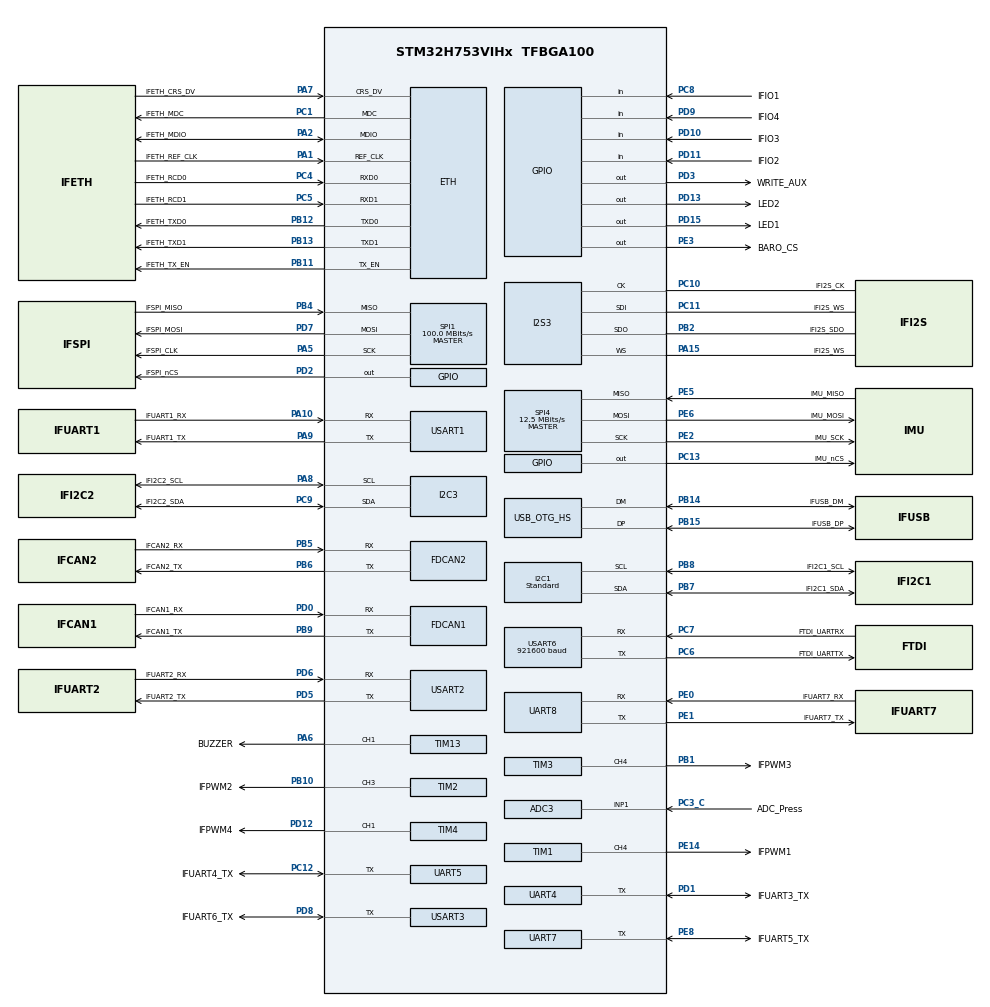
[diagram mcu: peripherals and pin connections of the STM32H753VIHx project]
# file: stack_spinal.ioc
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ADC3.Channel-1\#ChannelRegularConversion=ADC_CHANNEL_1
ADC3.NbrOfConversionFlag=1
ADC3.OffsetNumber-1\#ChannelRegularConversion=ADC_OFFSET_NONE
ADC3.OffsetSignedSaturation-1\#ChannelRegularConversion=DISABLE
ADC3.Rank-1\#ChannelRegularConversion=1
ADC3.SamplingTime-1\#ChannelRegularConversion=ADC_SAMPLETIME_1CYCLE_5
CORTEX_M7.AccessPermission-Cortex_Memory_Protection_Unit_Region0_Settings=MPU_REGION_FULL_ACCESS
CORTEX_M7.AccessPermission-Cortex_Memory_Protection_Unit_Region10_Settings=MPU_REGION_FULL_ACCESS
CORTEX_M7.AccessPermission-Cortex_Memory_Protection_Unit_Region11_Settings=MPU_REGION_FULL_ACCESS
CORTEX_M7.AccessPermission-Cortex_Memory_Protection_Unit_Region1_Settings=MPU_REGION_FULL_ACCESS
CORTEX_M7.AccessPermission-Cortex_Memory_Protection_Unit_Region2_Settings=MPU_REGION_FULL_ACCESS
CORTEX_M7.AccessPermission-Cortex_Memory_Protection_Unit_Region3_Settings=MPU_REGION_FULL_ACCESS
CORTEX_M7.AccessPermission-Cortex_Memory_Protection_Unit_Region4_Settings=MPU_REGION_FULL_ACCESS
CORTEX_M7.AccessPermission-Cortex_Memory_Protection_Unit_Region5_Settings=MPU_REGION_FULL_ACCESS
CORTEX_M7.AccessPermission-Cortex_Memory_Protection_Unit_Region6_Settings=MPU_REGION_FULL_ACCESS
CORTEX_M7.AccessPermission-Cortex_Memory_Protection_Unit_Region7_Settings=MPU_REGION_FULL_ACCESS
CORTEX_M7.AccessPermission-Cortex_Memory_Protection_Unit_Region9_Settings=MPU_REGION_FULL_ACCESS
CORTEX_M7.BaseAddress-Cortex_Memory_Protection_Unit_Region0_Settings=0x24040000
CORTEX_M7.BaseAddress-Cortex_Memory_Protection_Unit_Region10_Settings=0x24045100
CORTEX_M7.BaseAddress-Cortex_Memory_Protection_Unit_Region11_Settings=0x24045180
CORTEX_M7.BaseAddress-Cortex_Memory_Protection_Unit_Region1_Settings=0x24040000
CORTEX_M7.BaseAddress-Cortex_Memory_Protection_Unit_Region2_Settings=0x24044400
CORTEX_M7.BaseAddress-Cortex_Memory_Protection_Unit_Region3_Settings=0x30040000
CORTEX_M7.BaseAddress-Cortex_Memory_Protection_Unit_Region4_Settings=0x30044000
CORTEX_M7.BaseAddress-Cortex_Memory_Protection_Unit_Region5_Settings=0x30040000
CORTEX_M7.BaseAddress-Cortex_Memory_Protection_Unit_Region6_Settings=0x24044800
CORTEX_M7.BaseAddress-Cortex_Memory_Protection_Unit_Region7_Settings=0x24044C00
CORTEX_M7.BaseAddress-Cortex_Memory_Protection_Unit_Region8_Settings=0x24045000
CORTEX_M7.BaseAddress-Cortex_Memory_Protection_Unit_Region9_Settings=0x24045080
CORTEX_M7.CPU_DCache=Enabled
CORTEX_M7.CPU_ICache=Enabled
CORTEX_M7.Enable-Cortex_Memory_Protection_Unit_Region0_Settings=MPU_REGION_ENABLE
CORTEX_M7.Enable-Cortex_Memory_Protection_Unit_Region10_Settings=MPU_REGION_ENABLE
CORTEX_M7.Enable-Cortex_Memory_Protection_Unit_Region11_Settings=MPU_REGION_ENABLE
CORTEX_M7.Enable-Cortex_Memory_Protection_Unit_Region1_Settings=MPU_REGION_ENABLE
CORTEX_M7.Enable-Cortex_Memory_Protection_Unit_Region2_Settings=MPU_REGION_ENABLE
CORTEX_M7.Enable-Cortex_Memory_Protection_Unit_Region3_Settings=MPU_REGION_ENABLE
CORTEX_M7.Enable-Cortex_Memory_Protection_Unit_Region4_Settings=MPU_REGION_ENABLE
CORTEX_M7.Enable-Cortex_Memory_Protection_Unit_Region5_Settings=MPU_REGION_ENABLE
CORTEX_M7.Enable-Cortex_Memory_Protection_Unit_Region6_Settings=MPU_REGION_ENABLE
CORTEX_M7.Enable-Cortex_Memory_Protection_Unit_Region7_Settings=MPU_REGION_ENABLE
CORTEX_M7.Enable-Cortex_Memory_Protection_Unit_Region8_Settings=MPU_REGION_ENABLE
CORTEX_M7.Enable-Cortex_Memory_Protection_Unit_Region9_Settings=MPU_REGION_ENABLE
CORTEX_M7.IsBufferable-Cortex_Memory_Protection_Unit_Region5_Settings=MPU_ACCESS_BUFFERABLE
CORTEX_M7.IsCacheable-Cortex_Memory_Protection_Unit_Region1_Settings=MPU_ACCESS_CACHEABLE
CORTEX_M7.IsCacheable-Cortex_Memory_Protection_Unit_Region4_Settings=MPU_ACCESS_CACHEABLE
CORTEX_M7.IsShareable-Cortex_Memory_Protection_Unit_Region1_Settings=MPU_ACCESS_SHAREABLE
CORTEX_M7.MPU_Control=MPU_PRIVILEGED_DEFAULT
CORTEX_M7.Size-Cortex_Memory_Protection_Unit_Region0_Settings=MPU_REGION_SIZE_1KB
CORTEX_M7.Size-Cortex_Memory_Protection_Unit_Region10_Settings=MPU_REGION_SIZE_128B
CORTEX_M7.Size-Cortex_Memory_Protection_Unit_Region11_Settings=MPU_REGION_SIZE_128B
CORTEX_M7.Size-Cortex_Memory_Protection_Unit_Region1_Settings=MPU_REGION_SIZE_16KB
CORTEX_M7.Size-Cortex_Memory_Protection_Unit_Region2_Settings=MPU_REGION_SIZE_16KB
CORTEX_M7.Size-Cortex_Memory_Protection_Unit_Region3_Settings=MPU_REGION_SIZE_16KB
CORTEX_M7.Size-Cortex_Memory_Protection_Unit_Region4_Settings=MPU_REGION_SIZE_16KB
CORTEX_M7.Size-Cortex_Memory_Protection_Unit_Region5_Settings=MPU_REGION_SIZE_256B
CORTEX_M7.Size-Cortex_Memory_Protection_Unit_Region6_Settings=MPU_REGION_SIZE_1KB
CORTEX_M7.Size-Cortex_Memory_Protection_Unit_Region7_Settings=MPU_REGION_SIZE_1KB
CORTEX_M7.Size-Cortex_Memory_Protection_Unit_Region8_Settings=MPU_REGION_SIZE_128B
CORTEX_M7.Size-Cortex_Memory_Protection_Unit_Region9_Settings=MPU_REGION_SIZE_128B
CORTEX_M7.TypeExtField-Cortex_Memory_Protection_Unit_Region0_Settings=MPU_TEX_LEVEL1
CORTEX_M7.TypeExtField-Cortex_Memory_Protection_Unit_Region1_Settings=MPU_TEX_LEVEL0
CORTEX_M7.TypeExtField-Cortex_Memory_Protection_Unit_Region2_Settings=MPU_TEX_LEVEL1
CORTEX_M7.TypeExtField-Cortex_Memory_Protection_Unit_Region3_Settings=MPU_TEX_LEVEL1
CORTEX_M7.TypeExtField-Cortex_Memory_Protection_Unit_Region6_Settings=MPU_TEX_LEVEL1
CORTEX_M7.TypeExtField-Cortex_Memory_Protection_Unit_Region7_Settings=MPU_TEX_LEVEL1
Dma.Request0=USART6_RX
Dma.Request1=USART6_TX
Dma.USART6_RX.0.Direction=DMA_PERIPH_TO_MEMORY
Dma.USART6_RX.0.EventEnable=DISABLE
Dma.USART6_RX.0.FIFOMode=DMA_FIFOMODE_DISABLE
Dma.USART6_RX.0.Instance=DMA1_Stream0
Dma.USART6_RX.0.MemDataAlignment=DMA_MDATAALIGN_BYTE
Dma.USART6_RX.0.MemInc=DMA_MINC_ENABLE
Dma.USART6_RX.0.Mode=DMA_CIRCULAR
Dma.USART6_RX.0.PeriphDataAlignment=DMA_PDATAALIGN_BYTE
Dma.USART6_RX.0.PeriphInc=DMA_PINC_DISABLE
Dma.USART6_RX.0.Polarity=HAL_DMAMUX_REQ_GEN_RISING
Dma.USART6_RX.0.Priority=DMA_PRIORITY_VERY_HIGH
Dma.USART6_RX.0.RequestNumber=1
Dma.USART6_RX.0.SignalID=NONE
Dma.USART6_RX.0.SyncEnable=DISABLE
Dma.USART6_RX.0.SyncPolarity=HAL_DMAMUX_SYNC_NO_EVENT
Dma.USART6_RX.0.SyncRequestNumber=1
Dma.USART6_RX.0.SyncSignalID=NONE
Dma.USART6_TX.1.Direction=DMA_MEMORY_TO_PERIPH
Dma.USART6_TX.1.EventEnable=DISABLE
Dma.USART6_TX.1.FIFOMode=DMA_FIFOMODE_DISABLE
Dma.USART6_TX.1.Instance=DMA1_Stream1
Dma.USART6_TX.1.MemDataAlignment=DMA_MDATAALIGN_BYTE
Dma.USART6_TX.1.MemInc=DMA_MINC_ENABLE
Dma.USART6_TX.1.Mode=DMA_NORMAL
Dma.USART6_TX.1.PeriphDataAlignment=DMA_PDATAALIGN_BYTE
Dma.USART6_TX.1.PeriphInc=DMA_PINC_DISABLE
Dma.USART6_TX.1.Polarity=HAL_DMAMUX_REQ_GEN_RISING
Dma.USART6_TX.1.Priority=DMA_PRIORITY_VERY_HIGH
Dma.USART6_TX.1.RequestNumber=1
Dma.USART6_TX.1.SignalID=NONE
Dma.USART6_TX.1.SyncEnable=DISABLE
Dma.USART6_TX.1.SyncPolarity=HAL_DMAMUX_SYNC_NO_EVENT
Dma.USART6_TX.1.SyncRequestNumber=1
Dma.USART6_TX.1.SyncSignalID=NONE
ETH.MediaInterface=HAL_ETH_RMII_MODE
FREERTOS.BinarySemaphores01=coreTaskSem,Dynamic,NULL;uartTxSem,Dynamic,NULL
FREERTOS.Mutexes01=rosPubMutex,Dynamic,NULL;flightControlMutex,Dynamic,NULL
FREERTOS.Tasks01=coreTask,3,1024,coretaskFunc,As weak,NULL,Dynamic,NULL,NULL;rosSpinTask,0,256,rosSpinTaskFunc,As weak,NULL,Dynamic,NULL,NULL;idleTask,-3,128,idleTaskFunc,As weak,NULL,Dynamic,NULL,NULL;rosPublish,-1,128,rosPubliushTask,As weak,NULL,Dynamic,NULL,NULL;voltage,-2,256,voltageTask,Default,NULL,Dynamic,NULL,NULL
FREERTOS.Timers01=coreTaskTimer,coreTaskEvokeCb,osTimerPeriodic,Default,NULL,Dynamic,NULL
FREERTOS.configTIMER_TASK_PRIORITY=6
FREERTOS.configTOTAL_HEAP_SIZE=25600
FREERTOS.configUSE_NEWLIB_REENTRANT=1
FREERTOS.configUSE_TIMERS=1
I2C1.I2C_Speed_Mode=I2C_Standard
I2C1.Speed=100
I2C1.Timing=0x10C0ECFF
I2C3.Timing=0x10C0ECFF
I2S3.AudioFreq=I2S_AUDIOFREQ_96K
I2S3.ErrorAudioFreq=0.15 %
I2S3.FullDuplexMode=I2S_MODE_MASTER_FD
I2S3.Instance=SPI$Index
I2S3.RealAudioFreq=96.153 KHz
I2S3.VirtualMode=I2S_MODE_MASTER
LWIP.BSP.number=1
LWIP.GATEWAY_ADDRESS=192.168.025.253
LWIP.IP_ADDRESS=192.168.025.238
LWIP.LWIP_DHCP=0
LWIP.NETMASK_ADDRESS=255.255.255.000
LWIP.Version=v2.1.2_Cube
LWIP0.BSP.STBoard=false
LWIP0.BSP.api=BSP_COMPONENT_DRIVER
LWIP0.BSP.component=LAN8742
LWIP0.BSP.i2caddr=0
LWIP0.BSP.instance=LAN8742
LWIP0.BSP.name=Driver_PHY
LWIP0.BSP.solution=LAN8742
Mcu.Family=STM32H7
Mcu.Name=STM32H753VIHx
Mcu.Package=TFBGA100
NVIC.DMA1_Stream0_IRQn=true\:5\:0\:false\:false\:true\:true\:false\:true
NVIC.DMA1_Stream1_IRQn=true\:5\:0\:false\:false\:true\:true\:false\:true
NVIC.ETH_IRQn=true\:5\:0\:false\:false\:true\:true\:true\:true
NVIC.ETH_WKUP_IRQn=true\:5\:0\:false\:false\:true\:true\:true\:true
NVIC.PriorityGroup=NVIC_PRIORITYGROUP_4
NVIC.TIM8_UP_TIM13_IRQn=true\:0\:0\:false\:false\:true\:false\:false\:true
NVIC.TimeBase=TIM8_UP_TIM13_IRQn
NVIC.TimeBaseIP=TIM8
NVIC.USART6_IRQn=true\:5\:0\:false\:false\:true\:true\:true\:true
PA1.GPIO_Label=IFETH_REF_CLK
PA1.Mode=RMII
PA1.Signal=ETH_REF_CLK
PA10.GPIO_Label=IFUART1_RX
PA10.Mode=Asynchronous
PA10.Signal=USART1_RX
PA13\ (JTMS/SWDIO).Mode=Trace_Asynchronous_SW
PA13\ (JTMS/SWDIO).Signal=DEBUG_JTMS-SWDIO
PA14\ (JTCK/SWCLK).Mode=Trace_Asynchronous_SW
PA14\ (JTCK/SWCLK).Signal=DEBUG_JTCK-SWCLK
PA15\ (JTDI).GPIO_Label=IFI2S_WS
PA15\ (JTDI).Mode=Full_Duplex_Master
PA15\ (JTDI).Signal=I2S3_WS
PA2.GPIO_Label=IFETH_MDIO
PA2.Mode=RMII
PA2.Signal=ETH_MDIO
PA5.GPIO_Label=IFSPI_CLK
PA5.Mode=Full_Duplex_Master
PA5.Signal=SPI1_SCK
PA6.GPIO_Label=BUZZER
PA6.GPIO_Speed=GPIO_SPEED_FREQ_VERY_HIGH
PA6.Signal=S_TIM13_CH1
PA7.GPIO_Label=IFETH_CRS_DV
PA7.Mode=RMII
PA7.Signal=ETH_CRS_DV
PA8.GPIO_Label=IFI2C2_SCL
PA8.Mode=I2C
PA8.Signal=I2C3_SCL
PA9.GPIO_Label=IFUART1_TX
PA9.Mode=Asynchronous
PA9.Signal=USART1_TX
PB1.GPIO_Label=IFPWM3
PB1.Signal=S_TIM3_CH4
PB10.GPIO_Label=IFPWM2
PB10.Signal=S_TIM2_CH3
PB11.GPIO_Label=IFETH_TX_EN
PB11.Mode=RMII
PB11.Signal=ETH_TX_EN
PB12.GPIO_Label=IFETH_TXD0
PB12.Mode=RMII
PB12.Signal=ETH_TXD0
PB13.GPIO_Label=IFETH_TXD1
PB13.Mode=RMII
PB13.Signal=ETH_TXD1
PB14.GPIO_Label=IFUSB_DM
PB14.Mode=Host_FS
PB14.Signal=USB_OTG_HS_DM
PB15.GPIO_Label=IFUSB_DP
PB15.Mode=Host_FS
PB15.Signal=USB_OTG_HS_DP
PB2.GPIO_Label=IFI2S_SDO
PB2.Mode=Full_Duplex_Master
PB2.Signal=I2S3_SDO
PB3\ (JTDO/TRACESWO).Mode=Trace_Asynchronous_SW
PB3\ (JTDO/TRACESWO).Signal=DEBUG_JTDO-SWO
PB4\ (NJTRST).GPIO_Label=IFSPI_MISO
PB4\ (NJTRST).Mode=Full_Duplex_Master
PB4\ (NJTRST).Signal=SPI1_MISO
PB5.GPIO_Label=IFCAN2_RX
PB5.Mode=FDCAN_Activate
PB5.Signal=FDCAN2_RX
PB6.GPIO_Label=IFCAN2_TX
PB6.Mode=FDCAN_Activate
PB6.Signal=FDCAN2_TX
PB7.GPIO_Label=IFI2C1_SDA
PB7.GPIO_PuPd=GPIO_PULLUP
PB7.Mode=I2C
PB7.Signal=I2C1_SDA
PB8.GPIO_Label=IFI2C1_SCL
PB8.GPIO_PuPd=GPIO_PULLUP
PB8.Mode=I2C
PB8.Signal=I2C1_SCL
PB9.GPIO_Label=IFCAN1_TX
PB9.Mode=FDCAN_Activate
PB9.Signal=FDCAN1_TX
PC1.GPIO_Label=IFETH_MDC
PC1.Mode=RMII
PC1.Signal=ETH_MDC
PC10.GPIO_Label=IFI2S_CK
PC10.Mode=Full_Duplex_Master
PC10.Signal=I2S3_CK
PC11.GPIO_Label=IFI2S_WS
PC11.Mode=Full_Duplex_Master
PC11.Signal=I2S3_SDI
PC12.GPIO_Label=IFUART4_TX
PC12.Mode=Half_duplex(single_wire_mode)
PC12.Signal=UART5_TX
PC13.GPIO_Label=IMU_nCS
PC13.GPIO_Speed=GPIO_SPEED_FREQ_LOW
PC13.PinState=GPIO_PIN_SET
PC13.Signal=GPIO_Output
PC2_C.Signal=ADC3_INN1
PC3_C.GPIO_Label=ADC_Press
PC3_C.Mode=IN1-Single-Ended
PC3_C.Signal=ADC3_INP1
PC4.GPIO_Label=IFETH_RCD0
PC4.Mode=RMII
PC4.Signal=ETH_RXD0
PC5.GPIO_Label=IFETH_RCD1
PC5.Mode=RMII
PC5.Signal=ETH_RXD1
PC6.GPIO_Label=FTDI_UARTTX
PC6.Mode=Asynchronous
PC6.Signal=USART6_TX
PC7.GPIO_Label=FTDI_UARTRX
PC7.Mode=Asynchronous
PC7.Signal=USART6_RX
PC8.GPIO_Label=IFIO1
PC8.Signal=GPIO_Input
PC9.GPIO_Label=IFI2C2_SDA
PC9.Mode=I2C
PC9.Signal=I2C3_SDA
PD0.GPIO_Label=IFCAN1_RX
PD0.Mode=FDCAN_Activate
PD0.Signal=FDCAN1_RX
PD1.GPIO_Label=IFUART3_TX
PD1.Mode=Half_duplex(single_wire_mode)
PD1.Signal=UART4_TX
PD10.GPIO_Label=IFIO3
PD10.Signal=GPIO_Input
PD11.GPIO_Label=IFIO2
PD11.Signal=GPIO_Input
PD12.GPIO_Label=IFPWM4
PD12.Signal=S_TIM4_CH1
PD13.GPIO_Label=LED2
PD13.Signal=GPIO_Output
PD15.GPIO_Label=LED1
PD15.Signal=GPIO_Output
PD2.GPIO_Label=IFSPI_nCS
PD2.Signal=GPIO_Output
PD3.GPIO_Label=WRITE_AUX
PD3.Signal=GPIO_Output
PD5.GPIO_Label=IFUART2_TX
PD5.Mode=Asynchronous
PD5.Signal=USART2_TX
PD6.GPIO_Label=IFUART2_RX
PD6.Mode=Asynchronous
PD6.Signal=USART2_RX
PD7.GPIO_Label=IFSPI_MOSI
PD7.Mode=Full_Duplex_Master
PD7.Signal=SPI1_MOSI
PD8.GPIO_Label=IFUART6_TX
PD8.GPIO_PuPd=GPIO_PULLDOWN
PD8.GPIO_Speed=GPIO_SPEED_FREQ_HIGH
PD8.Mode=Half_duplex(single_wire_mode)
PD8.Signal=USART3_TX
PD9.GPIO_Label=IFIO4
PD9.Signal=GPIO_Input
PE0.GPIO_Label=IFUART7_RX
PE0.Mode=Asynchronous
PE0.Signal=UART8_RX
PE1.GPIO_Label=IFUART7_TX
PE1.Mode=Asynchronous
PE1.Signal=UART8_TX
PE14.GPIO_Label=IFPWM1
PE14.Signal=S_TIM1_CH4
PE2.GPIO_Label=IMU_SCK
PE2.GPIO_Speed=GPIO_SPEED_FREQ_MEDIUM
PE2.Mode=Full_Duplex_Master
PE2.Signal=SPI4_SCK
PE3.GPIO_Label=BARO_CS
PE3.PinState=GPIO_PIN_SET
PE3.Signal=GPIO_Output
PE5.GPIO_Label=IMU_MISO
PE5.GPIO_Speed=GPIO_SPEED_FREQ_MEDIUM
PE5.Mode=Full_Duplex_Master
PE5.Signal=SPI4_MISO
PE6.GPIO_Label=IMU_MOSI
PE6.GPIO_Speed=GPIO_SPEED_FREQ_MEDIUM
PE6.Mode=Full_Duplex_Master
PE6.Signal=SPI4_MOSI
PE8.GPIO_Label=IFUART5_TX
PE8.Mode=Half_duplex(single_wire_mode)
PE8.Signal=UART7_TX
PH0-OSC_IN\ (PH0).Mode=HSE-External-Oscillator
PH0-OSC_IN\ (PH0).Signal=RCC_OSC_IN
PH1-OSC_OUT\ (PH1).Mode=HSE-External-Oscillator
PH1-OSC_OUT\ (PH1).Signal=RCC_OSC_OUT
ProjectManager.HeapSize=0x200
ProjectManager.StackSize=0x400
ProjectManager.TargetToolchain=STM32CubeIDE
RCC.ADCFreq_Value=152000000
RCC.APB1Freq_Value=100000000
RCC.APB2Freq_Value=100000000
RCC.APB3Freq_Value=100000000
RCC.APB4Freq_Value=100000000
RCC.CortexFreq_Value=400000000
RCC.D1PPRE=RCC_APB3_DIV2
RCC.D2PPRE1=RCC_APB1_DIV2
RCC.D2PPRE2=RCC_APB2_DIV2
RCC.D3PPRE=RCC_APB4_DIV2
RCC.DIVM1=1
RCC.DIVM2=1
RCC.DIVN1=100
RCC.DIVN2=19
RCC.DIVP2=1
RCC.FDCANCLockSelection=RCC_FDCANCLKSOURCE_HSE
RCC.HCLKFreq_Value=200000000
RCC.HPRE=RCC_HCLK_DIV2
RCC.HSE_VALUE=8000000
RCC.PLL2FRACN=0
RCC.PLL3FRACN=0
RCC.PLLFRACN=0
RCC.PLLSourceVirtual=RCC_PLLSOURCE_HSE
RCC.SYSCLKFreq_VALUE=400000000
RCC.SYSCLKSource=RCC_SYSCLKSOURCE_PLLCLK
RCC.USBCLockSelection=RCC_USBCLKSOURCE_HSI48
RCC.USBFreq_Value=48000000
SH.S_TIM13_CH1.0=TIM13_CH1,PWM Generation1 CH1
SH.S_TIM1_CH4.0=TIM1_CH4,PWM Generation4 CH4
SH.S_TIM2_CH3.0=TIM2_CH3,PWM Generation3 CH3
SH.S_TIM3_CH4.0=TIM3_CH4,PWM Generation4 CH4
SH.S_TIM4_CH1.0=TIM4_CH1,PWM Generation1 CH1
SPI1.BaudRatePrescaler=SPI_BAUDRATEPRESCALER_4
SPI1.CalculateBaudRate=100.0 MBits/s
SPI1.Direction=SPI_DIRECTION_2LINES
SPI1.Mode=SPI_MODE_MASTER
SPI1.VirtualType=VM_MASTER
SPI4.BaudRatePrescaler=SPI_BAUDRATEPRESCALER_8
SPI4.CLKPhase=SPI_PHASE_2EDGE
SPI4.CLKPolarity=SPI_POLARITY_HIGH
SPI4.CalculateBaudRate=12.5 MBits/s
SPI4.DataSize=SPI_DATASIZE_8BIT
SPI4.Direction=SPI_DIRECTION_2LINES
SPI4.Mode=SPI_MODE_MASTER
SPI4.VirtualType=VM_MASTER
TIM1.Channel-PWM\ Generation4\ CH4=TIM_CHANNEL_4
TIM13.Channel=TIM_CHANNEL_1
TIM13.OC1Preload_PWM=DISABLE
TIM13.Period=499
TIM13.Prescaler=49
TIM2.Channel-PWM\ Generation3\ CH3=TIM_CHANNEL_3
TIM3.Channel-PWM\ Generation4\ CH4=TIM_CHANNEL_4
TIM4.Channel-PWM\ Generation1\ CH1=TIM_CHANNEL_1
USART1.VirtualMode-Asynchronous=VM_ASYNC
USART2.VirtualMode-Asynchronous=VM_ASYNC
USART3.BaudRate=1250000
USART3.FIFOMode=FIFOMODE_ENABLE
USART3.Parity=PARITY_EVEN
USART3.RXFIFOThreshold=RXFIFO_THRESHOLD_FULL
USART3.VirtualMode-Half_duplex(single_wire_mode)=VM_ASYNC
USART3.WordLength=WORDLENGTH_9B
USART6.BaudRate=921600
USART6.VirtualMode=VM_ASYNC
USB_OTG_HS.VirtualMode-Host_FS=Host_FS
VP_FREERTOS_VS_CMSIS_V1.Mode=CMSIS_V1
VP_LWIP_VS_Enabled.Mode=Enabled
VP_SYS_VS_tim8.Mode=TIM8
VP_TIM13_VS_ClockSourceINT.Mode=Enable_Timer
board=custom

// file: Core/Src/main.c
/* USER CODE BEGIN Header */
/**
  ******************************************************************************
  * @file           : main.c
  * @brief          : Main program body
  ******************************************************************************
  * @attention
  *
  * <h2><center>&copy; Copyright (c) 2025 STMicroelectronics.
  * All rights reserved.</center></h2>
  *
  * This software component is licensed by ST under Ultimate Liberty license
  * SLA0044, the "License"; You may not use this file except in compliance with
  * the License. You may obtain a copy of the License at:
  *                             www.st.com/SLA0044
  *
  ******************************************************************************
  */
/* USER CODE END Header */
#include "main.h"
#include "cmsis_os.h"
#include "lwip.h"

ADC_HandleTypeDef hadc3;

FDCAN_HandleTypeDef hfdcan1;
FDCAN_HandleTypeDef hfdcan2;

I2C_HandleTypeDef hi2c1;
I2C_HandleTypeDef hi2c3;

I2S_HandleTypeDef hi2s3;

SPI_HandleTypeDef hspi1;
SPI_HandleTypeDef hspi4;

TIM_HandleTypeDef htim1;
TIM_HandleTypeDef htim2;
TIM_HandleTypeDef htim3;
TIM_HandleTypeDef htim4;
TIM_HandleTypeDef htim13;

UART_HandleTypeDef huart4;
UART_HandleTypeDef huart5;
UART_HandleTypeDef huart7;
UART_HandleTypeDef huart8;
UART_HandleTypeDef huart1;
UART_HandleTypeDef huart2;
UART_HandleTypeDef huart3;
UART_HandleTypeDef huart6;
DMA_HandleTypeDef hdma_usart6_rx;
DMA_HandleTypeDef hdma_usart6_tx;

HCD_HandleTypeDef hhcd_USB_OTG_HS;

osThreadId coreTaskHandle;
osThreadId rosSpinTaskHandle;
osThreadId idleTaskHandle;
osThreadId rosPublishHandle;
osThreadId voltageHandle;
osTimerId coreTaskTimerHandle;
osMutexId rosPubMutexHandle;
osMutexId flightControlMutexHandle;
osSemaphoreId coreTaskSemHandle;
osSemaphoreId uartTxSemHandle;

void SystemClock_Config(void);
static void MPU_Config(void);
static void MX_GPIO_Init(void);
static void MX_USART6_UART_Init(void);
static void MX_FDCAN1_Init(void);
static void MX_FDCAN2_Init(void);
static void MX_I2C1_Init(void);
static void MX_I2C3_Init(void);
static void MX_SPI4_Init(void);
static void MX_I2S3_Init(void);
static void MX_UART8_Init(void);
static void MX_UART4_Init(void);
static void MX_UART5_Init(void);
static void MX_UART7_Init(void);
static void MX_USART1_UART_Init(void);
static void MX_USART2_UART_Init(void);
static void MX_USART3_UART_Init(void);
static void MX_USB_OTG_HS_HCD_Init(void);
static void MX_TIM1_Init(void);
static void MX_TIM2_Init(void);
static void MX_TIM3_Init(void);
static void MX_TIM4_Init(void);
static void MX_SPI1_Init(void);
static void MX_TIM13_Init(void);
static void MX_ADC3_Init(void);
static void MX_DMA_Init(void);
void coretaskFunc(void const * argument);
void rosSpinTaskFunc(void const * argument);
void idleTaskFunc(void const * argument);
void rosPubliushTask(void const * argument);
void voltageTask(void const * argument);
void coreTaskEvokeCb(void const * argument);

/* USER CODE BEGIN PFP */
void app_main();

/* USER CODE END PFP */

int main(void)
{

  /* MPU Configuration--------------------------------------------------------*/
  MPU_Config();

  /* Enable I-Cache---------------------------------------------------------*/
  SCB_EnableICache();

  /* Enable D-Cache---------------------------------------------------------*/
  SCB_EnableDCache();

  /* MCU Configuration--------------------------------------------------------*/

  /* Reset of all peripherals, Initializes the Flash interface and the Systick. */
  HAL_Init();

  /* Configure the system clock */
  SystemClock_Config();

  /* Initialize all configured peripherals */
  MX_GPIO_Init();
  MX_USART6_UART_Init();
  MX_FDCAN1_Init();
  MX_FDCAN2_Init();
  MX_I2C1_Init();
  MX_I2C3_Init();
  MX_SPI4_Init();
  MX_I2S3_Init();
  MX_UART8_Init();
  MX_UART4_Init();
  MX_UART5_Init();
  MX_UART7_Init();
  MX_USART1_UART_Init();
  MX_USART2_UART_Init();
  MX_USART3_UART_Init();
  MX_USB_OTG_HS_HCD_Init();
  MX_TIM1_Init();
  MX_TIM2_Init();
  MX_TIM3_Init();
  MX_TIM4_Init();
  MX_SPI1_Init();
  MX_TIM13_Init();
  MX_ADC3_Init();
  MX_DMA_Init();
  /* USER CODE BEGIN 2 */

  HAL_NVIC_DisableIRQ(DMA1_Stream0_IRQn); // we do not need DMA Interrupt for USART1 RX, circular mode

  /* USER CODE END 2 */

  /* Create the mutex(es) */
  /* definition and creation of rosPubMutex */
  osMutexDef(rosPubMutex);
  rosPubMutexHandle = osMutexCreate(osMutex(rosPubMutex));

  /* definition and creation of flightControlMutex */
  osMutexDef(flightControlMutex);
  flightControlMutexHandle = osMutexCreate(osMutex(flightControlMutex));

  /* Create the semaphores(s) */
  /* definition and creation of coreTaskSem */
  osSemaphoreDef(coreTaskSem);
  coreTaskSemHandle = osSemaphoreCreate(osSemaphore(coreTaskSem), 1);

  /* definition and creation of uartTxSem */
  osSemaphoreDef(uartTxSem);
  uartTxSemHandle = osSemaphoreCreate(osSemaphore(uartTxSem), 1);

  /* Create the timer(s) */
  /* definition and creation of coreTaskTimer */
  osTimerDef(coreTaskTimer, coreTaskEvokeCb);
  coreTaskTimerHandle = osTimerCreate(osTimer(coreTaskTimer), osTimerPeriodic, NULL);

  /* USER CODE BEGIN RTOS_TIMERS */
  /* start timers, add new ones, ... */
  osTimerStart(coreTaskTimerHandle, 1); // 1 ms (1kHz)
  /* USER CODE END RTOS_TIMERS */

  /* Create the thread(s) */
  /* definition and creation of coreTask */
  osThreadDef(coreTask, coretaskFunc, osPriorityRealtime, 0, 1024);
  coreTaskHandle = osThreadCreate(osThread(coreTask), NULL);

  /* definition and creation of rosSpinTask */
  osThreadDef(rosSpinTask, rosSpinTaskFunc, osPriorityNormal, 0, 256);
  rosSpinTaskHandle = osThreadCreate(osThread(rosSpinTask), NULL);

  /* definition and creation of idleTask */
  osThreadDef(idleTask, idleTaskFunc, osPriorityIdle, 0, 128);
  idleTaskHandle = osThreadCreate(osThread(idleTask), NULL);

  /* definition and creation of rosPublish */
  osThreadDef(rosPublish, rosPubliushTask, osPriorityBelowNormal, 0, 128);
  rosPublishHandle = osThreadCreate(osThread(rosPublish), NULL);

  /* definition and creation of voltage */
  osThreadDef(voltage, voltageTask, osPriorityLow, 0, 256);
  voltageHandle = osThreadCreate(osThread(voltage), NULL);

  /* Start scheduler */
  osKernelStart();

  /* We should never get here as control is now taken by the scheduler */
  /* Infinite loop */
  /* USER CODE BEGIN WHILE */
  //app_main();

  while (1)
  {
    /* USER CODE END WHILE */

  }
}

void SystemClock_Config(void)
{
  RCC_OscInitTypeDef RCC_OscInitStruct = {0};
  RCC_ClkInitTypeDef RCC_ClkInitStruct = {0};
  RCC_PeriphCLKInitTypeDef PeriphClkInitStruct = {0};

  /** Supply configuration update enable
  */
  HAL_PWREx_ConfigSupply(PWR_LDO_SUPPLY);
  /** Configure the main internal regulator output voltage
  */
  __HAL_PWR_VOLTAGESCALING_CONFIG(PWR_REGULATOR_VOLTAGE_SCALE1);

  while(!__HAL_PWR_GET_FLAG(PWR_FLAG_VOSRDY)) {}
  /** Macro to configure the PLL clock source
  */
  __HAL_RCC_PLL_PLLSOURCE_CONFIG(RCC_PLLSOURCE_HSE);
  /** Initializes the RCC Oscillators according to the specified parameters
  * in the RCC_OscInitTypeDef structure.
  */
  RCC_OscInitStruct.OscillatorType = RCC_OSCILLATORTYPE_HSI48|RCC_OSCILLATORTYPE_HSE;
  RCC_OscInitStruct.HSEState = RCC_HSE_ON;
  RCC_OscInitStruct.HSI48State = RCC_HSI48_ON;
  RCC_OscInitStruct.PLL.PLLState = RCC_PLL_ON;
  RCC_OscInitStruct.PLL.PLLSource = RCC_PLLSOURCE_HSE;
  RCC_OscInitStruct.PLL.PLLM = 1;
  RCC_OscInitStruct.PLL.PLLN = 100;
  RCC_OscInitStruct.PLL.PLLP = 2;
  RCC_OscInitStruct.PLL.PLLQ = 2;
  RCC_OscInitStruct.PLL.PLLR = 2;
  RCC_OscInitStruct.PLL.PLLRGE = RCC_PLL1VCIRANGE_3;
  RCC_OscInitStruct.PLL.PLLVCOSEL = RCC_PLL1VCOWIDE;
  RCC_OscInitStruct.PLL.PLLFRACN = 0;
  if (HAL_RCC_OscConfig(&RCC_OscInitStruct) != HAL_OK)
  {
    Error_Handler();
  }
  /** Initializes the CPU, AHB and APB buses clocks
  */
  RCC_ClkInitStruct.ClockType = RCC_CLOCKTYPE_HCLK|RCC_CLOCKTYPE_SYSCLK
                              |RCC_CLOCKTYPE_PCLK1|RCC_CLOCKTYPE_PCLK2
                              |RCC_CLOCKTYPE_D3PCLK1|RCC_CLOCKTYPE_D1PCLK1;
  RCC_ClkInitStruct.SYSCLKSource = RCC_SYSCLKSOURCE_PLLCLK;
  RCC_ClkInitStruct.SYSCLKDivider = RCC_SYSCLK_DIV1;
  RCC_ClkInitStruct.AHBCLKDivider = RCC_HCLK_DIV2;
  RCC_ClkInitStruct.APB3CLKDivider = RCC_APB3_DIV2;
  RCC_ClkInitStruct.APB1CLKDivider = RCC_APB1_DIV2;
  RCC_ClkInitStruct.APB2CLKDivider = RCC_APB2_DIV2;
  RCC_ClkInitStruct.APB4CLKDivider = RCC_APB4_DIV2;

  if (HAL_RCC_ClockConfig(&RCC_ClkInitStruct, FLASH_LATENCY_2) != HAL_OK)
  {
    Error_Handler();
  }
  PeriphClkInitStruct.PeriphClockSelection = RCC_PERIPHCLK_USART3|RCC_PERIPHCLK_USART2
                              |RCC_PERIPHCLK_UART4|RCC_PERIPHCLK_UART7
                              |RCC_PERIPHCLK_USART6|RCC_PERIPHCLK_FDCAN
                              |RCC_PERIPHCLK_USART1|RCC_PERIPHCLK_UART8
                              |RCC_PERIPHCLK_UART5|RCC_PERIPHCLK_SPI4
                              |RCC_PERIPHCLK_SPI3|RCC_PERIPHCLK_SPI1
                              |RCC_PERIPHCLK_I2C3|RCC_PERIPHCLK_ADC
                              |RCC_PERIPHCLK_I2C1|RCC_PERIPHCLK_USB;
  PeriphClkInitStruct.PLL2.PLL2M = 1;
  PeriphClkInitStruct.PLL2.PLL2N = 19;
  PeriphClkInitStruct.PLL2.PLL2P = 1;
  PeriphClkInitStruct.PLL2.PLL2Q = 2;
  PeriphClkInitStruct.PLL2.PLL2R = 2;
  PeriphClkInitStruct.PLL2.PLL2RGE = RCC_PLL2VCIRANGE_3;
  PeriphClkInitStruct.PLL2.PLL2VCOSEL = RCC_PLL2VCOMEDIUM;
  PeriphClkInitStruct.PLL2.PLL2FRACN = 0;
  PeriphClkInitStruct.Spi123ClockSelection = RCC_SPI123CLKSOURCE_PLL;
  PeriphClkInitStruct.Spi45ClockSelection = RCC_SPI45CLKSOURCE_D2PCLK1;
  PeriphClkInitStruct.FdcanClockSelection = RCC_FDCANCLKSOURCE_HSE;
  PeriphClkInitStruct.Usart234578ClockSelection = RCC_USART234578CLKSOURCE_D2PCLK1;
  PeriphClkInitStruct.Usart16ClockSelection = RCC_USART16CLKSOURCE_D2PCLK2;
  PeriphClkInitStruct.I2c123ClockSelection = RCC_I2C123CLKSOURCE_D2PCLK1;
  PeriphClkInitStruct.UsbClockSelection = RCC_USBCLKSOURCE_HSI48;
  PeriphClkInitStruct.AdcClockSelection = RCC_ADCCLKSOURCE_PLL2;
  if (HAL_RCCEx_PeriphCLKConfig(&PeriphClkInitStruct) != HAL_OK)
  {
    Error_Handler();
  }
  /** Enable USB Voltage detector
  */
  HAL_PWREx_EnableUSBVoltageDetector();
}

static void MX_ADC3_Init(void)
{

  ADC_ChannelConfTypeDef sConfig = {0};

  /** Common config
  */
  hadc3.Instance = ADC3;
  hadc3.Init.ClockPrescaler = ADC_CLOCK_ASYNC_DIV6;
  hadc3.Init.Resolution = ADC_RESOLUTION_16B;
  hadc3.Init.ScanConvMode = ADC_SCAN_DISABLE;
  hadc3.Init.EOCSelection = ADC_EOC_SINGLE_CONV;
  hadc3.Init.LowPowerAutoWait = DISABLE;
  hadc3.Init.ContinuousConvMode = DISABLE;
  hadc3.Init.NbrOfConversion = 1;
  hadc3.Init.DiscontinuousConvMode = DISABLE;
  hadc3.Init.ExternalTrigConv = ADC_SOFTWARE_START;
  hadc3.Init.ExternalTrigConvEdge = ADC_EXTERNALTRIGCONVEDGE_NONE;
  hadc3.Init.ConversionDataManagement = ADC_CONVERSIONDATA_DR;
  hadc3.Init.Overrun = ADC_OVR_DATA_PRESERVED;
  hadc3.Init.LeftBitShift = ADC_LEFTBITSHIFT_NONE;
  hadc3.Init.OversamplingMode = DISABLE;
  if (HAL_ADC_Init(&hadc3) != HAL_OK)
  {
    Error_Handler();
  }
  /** Configure Regular Channel
  */
  sConfig.Channel = ADC_CHANNEL_1;
  sConfig.Rank = ADC_REGULAR_RANK_1;
  sConfig.SamplingTime = ADC_SAMPLETIME_1CYCLE_5;
  sConfig.SingleDiff = ADC_SINGLE_ENDED;
  sConfig.OffsetNumber = ADC_OFFSET_NONE;
  sConfig.Offset = 0;
  sConfig.OffsetSignedSaturation = DISABLE;
  if (HAL_ADC_ConfigChannel(&hadc3, &sConfig) != HAL_OK)
  {
    Error_Handler();
  }

}

static void MX_FDCAN1_Init(void)
{

  hfdcan1.Instance = FDCAN1;
  hfdcan1.Init.FrameFormat = FDCAN_FRAME_CLASSIC;
  hfdcan1.Init.Mode = FDCAN_MODE_NORMAL;
  hfdcan1.Init.AutoRetransmission = DISABLE;
  hfdcan1.Init.TransmitPause = DISABLE;
  hfdcan1.Init.ProtocolException = DISABLE;
  hfdcan1.Init.NominalPrescaler = 1;
  hfdcan1.Init.NominalSyncJumpWidth = 1;
  hfdcan1.Init.NominalTimeSeg1 = 2;
  hfdcan1.Init.NominalTimeSeg2 = 2;
  hfdcan1.Init.DataPrescaler = 1;
  hfdcan1.Init.DataSyncJumpWidth = 1;
  hfdcan1.Init.DataTimeSeg1 = 1;
  hfdcan1.Init.DataTimeSeg2 = 1;
  hfdcan1.Init.MessageRAMOffset = 0;
  hfdcan1.Init.StdFiltersNbr = 0;
  hfdcan1.Init.ExtFiltersNbr = 0;
  hfdcan1.Init.RxFifo0ElmtsNbr = 0;
  hfdcan1.Init.RxFifo0ElmtSize = FDCAN_DATA_BYTES_8;
  hfdcan1.Init.RxFifo1ElmtsNbr = 0;
  hfdcan1.Init.RxFifo1ElmtSize = FDCAN_DATA_BYTES_8;
  hfdcan1.Init.RxBuffersNbr = 0;
  hfdcan1.Init.RxBufferSize = FDCAN_DATA_BYTES_8;
  hfdcan1.Init.TxEventsNbr = 0;
  hfdcan1.Init.TxBuffersNbr = 0;
  hfdcan1.Init.TxFifoQueueElmtsNbr = 0;
  hfdcan1.Init.TxFifoQueueMode = FDCAN_TX_FIFO_OPERATION;
  hfdcan1.Init.TxElmtSize = FDCAN_DATA_BYTES_8;
  if (HAL_FDCAN_Init(&hfdcan1) != HAL_OK)
  {
    Error_Handler();
  }

}

static void MX_FDCAN2_Init(void)
{

  hfdcan2.Instance = FDCAN2;
  hfdcan2.Init.FrameFormat = FDCAN_FRAME_CLASSIC;
  hfdcan2.Init.Mode = FDCAN_MODE_NORMAL;
  hfdcan2.Init.AutoRetransmission = DISABLE;
  hfdcan2.Init.TransmitPause = DISABLE;
  hfdcan2.Init.ProtocolException = DISABLE;
  hfdcan2.Init.NominalPrescaler = 1;
  hfdcan2.Init.NominalSyncJumpWidth = 1;
  hfdcan2.Init.NominalTimeSeg1 = 2;
  hfdcan2.Init.NominalTimeSeg2 = 2;
  hfdcan2.Init.DataPrescaler = 1;
  hfdcan2.Init.DataSyncJumpWidth = 1;
  hfdcan2.Init.DataTimeSeg1 = 1;
  hfdcan2.Init.DataTimeSeg2 = 1;
  hfdcan2.Init.MessageRAMOffset = 0;
  hfdcan2.Init.StdFiltersNbr = 0;
  hfdcan2.Init.ExtFiltersNbr = 0;
  hfdcan2.Init.RxFifo0ElmtsNbr = 0;
  hfdcan2.Init.RxFifo0ElmtSize = FDCAN_DATA_BYTES_8;
  hfdcan2.Init.RxFifo1ElmtsNbr = 0;
  hfdcan2.Init.RxFifo1ElmtSize = FDCAN_DATA_BYTES_8;
  hfdcan2.Init.RxBuffersNbr = 0;
  hfdcan2.Init.RxBufferSize = FDCAN_DATA_BYTES_8;
  hfdcan2.Init.TxEventsNbr = 0;
  hfdcan2.Init.TxBuffersNbr = 0;
  hfdcan2.Init.TxFifoQueueElmtsNbr = 0;
  hfdcan2.Init.TxFifoQueueMode = FDCAN_TX_FIFO_OPERATION;
  hfdcan2.Init.TxElmtSize = FDCAN_DATA_BYTES_8;
  if (HAL_FDCAN_Init(&hfdcan2) != HAL_OK)
  {
    Error_Handler();
  }

}

static void MX_I2C1_Init(void)
{

  hi2c1.Instance = I2C1;
  hi2c1.Init.Timing = 0x10C0ECFF;
  hi2c1.Init.OwnAddress1 = 0;
  hi2c1.Init.AddressingMode = I2C_ADDRESSINGMODE_7BIT;
  hi2c1.Init.DualAddressMode = I2C_DUALADDRESS_DISABLE;
  hi2c1.Init.OwnAddress2 = 0;
  hi2c1.Init.OwnAddress2Masks = I2C_OA2_NOMASK;
  hi2c1.Init.GeneralCallMode = I2C_GENERALCALL_DISABLE;
  hi2c1.Init.NoStretchMode = I2C_NOSTRETCH_DISABLE;
  if (HAL_I2C_Init(&hi2c1) != HAL_OK)
  {
    Error_Handler();
  }
  /** Configure Analogue filter
  */
  if (HAL_I2CEx_ConfigAnalogFilter(&hi2c1, I2C_ANALOGFILTER_ENABLE) != HAL_OK)
  {
    Error_Handler();
  }
  /** Configure Digital filter
  */
  if (HAL_I2CEx_ConfigDigitalFilter(&hi2c1, 0) != HAL_OK)
  {
    Error_Handler();
  }

}

static void MX_I2C3_Init(void)
{

  hi2c3.Instance = I2C3;
  hi2c3.Init.Timing = 0x10C0ECFF;
  hi2c3.Init.OwnAddress1 = 0;
  hi2c3.Init.AddressingMode = I2C_ADDRESSINGMODE_7BIT;
  hi2c3.Init.DualAddressMode = I2C_DUALADDRESS_DISABLE;
  hi2c3.Init.OwnAddress2 = 0;
  hi2c3.Init.OwnAddress2Masks = I2C_OA2_NOMASK;
  hi2c3.Init.GeneralCallMode = I2C_GENERALCALL_DISABLE;
  hi2c3.Init.NoStretchMode = I2C_NOSTRETCH_DISABLE;
  if (HAL_I2C_Init(&hi2c3) != HAL_OK)
  {
    Error_Handler();
  }
  /** Configure Analogue filter
  */
  if (HAL_I2CEx_ConfigAnalogFilter(&hi2c3, I2C_ANALOGFILTER_ENABLE) != HAL_OK)
  {
    Error_Handler();
  }
  /** Configure Digital filter
  */
  if (HAL_I2CEx_ConfigDigitalFilter(&hi2c3, 0) != HAL_OK)
  {
    Error_Handler();
  }

}

static void MX_I2S3_Init(void)
{

  hi2s3.Instance = SPI3;
  hi2s3.Init.Mode = I2S_MODE_MASTER_TX;
  hi2s3.Init.Standard = I2S_STANDARD_PHILIPS;
  hi2s3.Init.DataFormat = I2S_DATAFORMAT_16B;
  hi2s3.Init.MCLKOutput = I2S_MCLKOUTPUT_DISABLE;
  hi2s3.Init.AudioFreq = I2S_AUDIOFREQ_96K;
  hi2s3.Init.CPOL = I2S_CPOL_LOW;
  hi2s3.Init.FirstBit = I2S_FIRSTBIT_MSB;
  hi2s3.Init.WSInversion = I2S_WS_INVERSION_DISABLE;
  hi2s3.Init.Data24BitAlignment = I2S_DATA_24BIT_ALIGNMENT_RIGHT;
  hi2s3.Init.MasterKeepIOState = I2S_MASTER_KEEP_IO_STATE_DISABLE;
  if (HAL_I2S_Init(&hi2s3) != HAL_OK)
  {
    Error_Handler();
  }

}

static void MX_SPI1_Init(void)
{

  /* SPI1 parameter configuration*/
  hspi1.Instance = SPI1;
  hspi1.Init.Mode = SPI_MODE_MASTER;
  hspi1.Init.Direction = SPI_DIRECTION_2LINES;
  hspi1.Init.DataSize = SPI_DATASIZE_4BIT;
  hspi1.Init.CLKPolarity = SPI_POLARITY_LOW;
  hspi1.Init.CLKPhase = SPI_PHASE_1EDGE;
  hspi1.Init.NSS = SPI_NSS_SOFT;
  hspi1.Init.BaudRatePrescaler = SPI_BAUDRATEPRESCALER_4;
  hspi1.Init.FirstBit = SPI_FIRSTBIT_MSB;
  hspi1.Init.TIMode = SPI_TIMODE_DISABLE;
  hspi1.Init.CRCCalculation = SPI_CRCCALCULATION_DISABLE;
  hspi1.Init.CRCPolynomial = 0x0;
  hspi1.Init.NSSPMode = SPI_NSS_PULSE_ENABLE;
  hspi1.Init.NSSPolarity = SPI_NSS_POLARITY_LOW;
  hspi1.Init.FifoThreshold = SPI_FIFO_THRESHOLD_01DATA;
  hspi1.Init.TxCRCInitializationPattern = SPI_CRC_INITIALIZATION_ALL_ZERO_PATTERN;
  hspi1.Init.RxCRCInitializationPattern = SPI_CRC_INITIALIZATION_ALL_ZERO_PATTERN;
  hspi1.Init.MasterSSIdleness = SPI_MASTER_SS_IDLENESS_00CYCLE;
  hspi1.Init.MasterInterDataIdleness = SPI_MASTER_INTERDATA_IDLENESS_00CYCLE;
  hspi1.Init.MasterReceiverAutoSusp = SPI_MASTER_RX_AUTOSUSP_DISABLE;
  hspi1.Init.MasterKeepIOState = SPI_MASTER_KEEP_IO_STATE_DISABLE;
  hspi1.Init.IOSwap = SPI_IO_SWAP_DISABLE;
  if (HAL_SPI_Init(&hspi1) != HAL_OK)
  {
    Error_Handler();
  }

}

static void MX_SPI4_Init(void)
{

  /* SPI4 parameter configuration*/
  hspi4.Instance = SPI4;
  hspi4.Init.Mode = SPI_MODE_MASTER;
  hspi4.Init.Direction = SPI_DIRECTION_2LINES;
  hspi4.Init.DataSize = SPI_DATASIZE_8BIT;
  hspi4.Init.CLKPolarity = SPI_POLARITY_HIGH;
  hspi4.Init.CLKPhase = SPI_PHASE_2EDGE;
  hspi4.Init.NSS = SPI_NSS_SOFT;
  hspi4.Init.BaudRatePrescaler = SPI_BAUDRATEPRESCALER_8;
  hspi4.Init.FirstBit = SPI_FIRSTBIT_MSB;
  hspi4.Init.TIMode = SPI_TIMODE_DISABLE;
  hspi4.Init.CRCCalculation = SPI_CRCCALCULATION_DISABLE;
  hspi4.Init.CRCPolynomial = 0x0;
  hspi4.Init.NSSPMode = SPI_NSS_PULSE_ENABLE;
  hspi4.Init.NSSPolarity = SPI_NSS_POLARITY_LOW;
  hspi4.Init.FifoThreshold = SPI_FIFO_THRESHOLD_01DATA;
  hspi4.Init.TxCRCInitializationPattern = SPI_CRC_INITIALIZATION_ALL_ZERO_PATTERN;
  hspi4.Init.RxCRCInitializationPattern = SPI_CRC_INITIALIZATION_ALL_ZERO_PATTERN;
  hspi4.Init.MasterSSIdleness = SPI_MASTER_SS_IDLENESS_00CYCLE;
  hspi4.Init.MasterInterDataIdleness = SPI_MASTER_INTERDATA_IDLENESS_00CYCLE;
  hspi4.Init.MasterReceiverAutoSusp = SPI_MASTER_RX_AUTOSUSP_DISABLE;
  hspi4.Init.MasterKeepIOState = SPI_MASTER_KEEP_IO_STATE_DISABLE;
  hspi4.Init.IOSwap = SPI_IO_SWAP_DISABLE;
  if (HAL_SPI_Init(&hspi4) != HAL_OK)
  {
    Error_Handler();
  }

}

static void MX_TIM1_Init(void)
{

  TIM_MasterConfigTypeDef sMasterConfig = {0};
  TIM_OC_InitTypeDef sConfigOC = {0};
  TIM_BreakDeadTimeConfigTypeDef sBreakDeadTimeConfig = {0};

  htim1.Instance = TIM1;
  htim1.Init.Prescaler = 0;
  htim1.Init.CounterMode = TIM_COUNTERMODE_UP;
  htim1.Init.Period = 65535;
  htim1.Init.ClockDivision = TIM_CLOCKDIVISION_DIV1;
  htim1.Init.RepetitionCounter = 0;
  htim1.Init.AutoReloadPreload = TIM_AUTORELOAD_PRELOAD_DISABLE;
  if (HAL_TIM_PWM_Init(&htim1) != HAL_OK)
  {
    Error_Handler();
  }
  sMasterConfig.MasterOutputTrigger = TIM_TRGO_RESET;
  sMasterConfig.MasterOutputTrigger2 = TIM_TRGO2_RESET;
  sMasterConfig.MasterSlaveMode = TIM_MASTERSLAVEMODE_DISABLE;
  if (HAL_TIMEx_MasterConfigSynchronization(&htim1, &sMasterConfig) != HAL_OK)
  {
    Error_Handler();
  }
  sConfigOC.OCMode = TIM_OCMODE_PWM1;
  sConfigOC.Pulse = 0;
  sConfigOC.OCPolarity = TIM_OCPOLARITY_HIGH;
  sConfigOC.OCFastMode = TIM_OCFAST_DISABLE;
  sConfigOC.OCIdleState = TIM_OCIDLESTATE_RESET;
  sConfigOC.OCNIdleState = TIM_OCNIDLESTATE_RESET;
  if (HAL_TIM_PWM_ConfigChannel(&htim1, &sConfigOC, TIM_CHANNEL_4) != HAL_OK)
  {
    Error_Handler();
  }
  sBreakDeadTimeConfig.OffStateRunMode = TIM_OSSR_DISABLE;
  sBreakDeadTimeConfig.OffStateIDLEMode = TIM_OSSI_DISABLE;
  sBreakDeadTimeConfig.LockLevel = TIM_LOCKLEVEL_OFF;
  sBreakDeadTimeConfig.DeadTime = 0;
  sBreakDeadTimeConfig.BreakState = TIM_BREAK_DISABLE;
  sBreakDeadTimeConfig.BreakPolarity = TIM_BREAKPOLARITY_HIGH;
  sBreakDeadTimeConfig.BreakFilter = 0;
  sBreakDeadTimeConfig.Break2State = TIM_BREAK2_DISABLE;
  sBreakDeadTimeConfig.Break2Polarity = TIM_BREAK2POLARITY_HIGH;
  sBreakDeadTimeConfig.Break2Filter = 0;
  sBreakDeadTimeConfig.AutomaticOutput = TIM_AUTOMATICOUTPUT_DISABLE;
  if (HAL_TIMEx_ConfigBreakDeadTime(&htim1, &sBreakDeadTimeConfig) != HAL_OK)
  {
    Error_Handler();
  }
  HAL_TIM_MspPostInit(&htim1);

}

static void MX_TIM2_Init(void)
{

  TIM_MasterConfigTypeDef sMasterConfig = {0};
  TIM_OC_InitTypeDef sConfigOC = {0};

  htim2.Instance = TIM2;
  htim2.Init.Prescaler = 0;
  htim2.Init.CounterMode = TIM_COUNTERMODE_UP;
  htim2.Init.Period = 4294967295;
  htim2.Init.ClockDivision = TIM_CLOCKDIVISION_DIV1;
  htim2.Init.AutoReloadPreload = TIM_AUTORELOAD_PRELOAD_DISABLE;
  if (HAL_TIM_PWM_Init(&htim2) != HAL_OK)
  {
    Error_Handler();
  }
  sMasterConfig.MasterOutputTrigger = TIM_TRGO_RESET;
  sMasterConfig.MasterSlaveMode = TIM_MASTERSLAVEMODE_DISABLE;
  if (HAL_TIMEx_MasterConfigSynchronization(&htim2, &sMasterConfig) != HAL_OK)
  {
    Error_Handler();
  }
  sConfigOC.OCMode = TIM_OCMODE_PWM1;
  sConfigOC.Pulse = 0;
  sConfigOC.OCPolarity = TIM_OCPOLARITY_HIGH;
  sConfigOC.OCFastMode = TIM_OCFAST_DISABLE;
  if (HAL_TIM_PWM_ConfigChannel(&htim2, &sConfigOC, TIM_CHANNEL_3) != HAL_OK)
  {
    Error_Handler();
  }
  HAL_TIM_MspPostInit(&htim2);

}

static void MX_TIM3_Init(void)
{

  TIM_MasterConfigTypeDef sMasterConfig = {0};
  TIM_OC_InitTypeDef sConfigOC = {0};

  htim3.Instance = TIM3;
  htim3.Init.Prescaler = 0;
  htim3.Init.CounterMode = TIM_COUNTERMODE_UP;
  htim3.Init.Period = 65535;
  htim3.Init.ClockDivision = TIM_CLOCKDIVISION_DIV1;
  htim3.Init.AutoReloadPreload = TIM_AUTORELOAD_PRELOAD_DISABLE;
  if (HAL_TIM_PWM_Init(&htim3) != HAL_OK)
  {
    Error_Handler();
  }
  sMasterConfig.MasterOutputTrigger = TIM_TRGO_RESET;
  sMasterConfig.MasterSlaveMode = TIM_MASTERSLAVEMODE_DISABLE;
  if (HAL_TIMEx_MasterConfigSynchronization(&htim3, &sMasterConfig) != HAL_OK)
  {
    Error_Handler();
  }
  sConfigOC.OCMode = TIM_OCMODE_PWM1;
  sConfigOC.Pulse = 0;
  sConfigOC.OCPolarity = TIM_OCPOLARITY_HIGH;
  sConfigOC.OCFastMode = TIM_OCFAST_DISABLE;
  if (HAL_TIM_PWM_ConfigChannel(&htim3, &sConfigOC, TIM_CHANNEL_4) != HAL_OK)
  {
    Error_Handler();
  }
  HAL_TIM_MspPostInit(&htim3);

}

static void MX_TIM4_Init(void)
{

  TIM_MasterConfigTypeDef sMasterConfig = {0};
  TIM_OC_InitTypeDef sConfigOC = {0};

  htim4.Instance = TIM4;
  htim4.Init.Prescaler = 0;
  htim4.Init.CounterMode = TIM_COUNTERMODE_UP;
  htim4.Init.Period = 65535;
  htim4.Init.ClockDivision = TIM_CLOCKDIVISION_DIV1;
  htim4.Init.AutoReloadPreload = TIM_AUTORELOAD_PRELOAD_DISABLE;
  if (HAL_TIM_PWM_Init(&htim4) != HAL_OK)
  {
    Error_Handler();
  }
  sMasterConfig.MasterOutputTrigger = TIM_TRGO_RESET;
  sMasterConfig.MasterSlaveMode = TIM_MASTERSLAVEMODE_DISABLE;
  if (HAL_TIMEx_MasterConfigSynchronization(&htim4, &sMasterConfig) != HAL_OK)
  {
    Error_Handler();
  }
  sConfigOC.OCMode = TIM_OCMODE_PWM1;
  sConfigOC.Pulse = 0;
  sConfigOC.OCPolarity = TIM_OCPOLARITY_HIGH;
  sConfigOC.OCFastMode = TIM_OCFAST_DISABLE;
  if (HAL_TIM_PWM_ConfigChannel(&htim4, &sConfigOC, TIM_CHANNEL_1) != HAL_OK)
  {
    Error_Handler();
  }
  HAL_TIM_MspPostInit(&htim4);

}

static void MX_TIM13_Init(void)
{

  TIM_OC_InitTypeDef sConfigOC = {0};

  htim13.Instance = TIM13;
  htim13.Init.Prescaler = 49;
  htim13.Init.CounterMode = TIM_COUNTERMODE_UP;
  htim13.Init.Period = 499;
  htim13.Init.ClockDivision = TIM_CLOCKDIVISION_DIV1;
  htim13.Init.AutoReloadPreload = TIM_AUTORELOAD_PRELOAD_DISABLE;
  if (HAL_TIM_Base_Init(&htim13) != HAL_OK)
  {
    Error_Handler();
  }
  if (HAL_TIM_PWM_Init(&htim13) != HAL_OK)
  {
    Error_Handler();
  }
  sConfigOC.OCMode = TIM_OCMODE_PWM1;
  sConfigOC.Pulse = 0;
  sConfigOC.OCPolarity = TIM_OCPOLARITY_HIGH;
  sConfigOC.OCFastMode = TIM_OCFAST_DISABLE;
  if (HAL_TIM_PWM_ConfigChannel(&htim13, &sConfigOC, TIM_CHANNEL_1) != HAL_OK)
  {
    Error_Handler();
  }
  __HAL_TIM_DISABLE_OCxPRELOAD(&htim13, TIM_CHANNEL_1);
  HAL_TIM_MspPostInit(&htim13);

}

static void MX_UART4_Init(void)
{

  huart4.Instance = UART4;
  huart4.Init.BaudRate = 115200;
  huart4.Init.WordLength = UART_WORDLENGTH_8B;
  huart4.Init.StopBits = UART_STOPBITS_1;
  huart4.Init.Parity = UART_PARITY_NONE;
  huart4.Init.Mode = UART_MODE_TX_RX;
  huart4.Init.HwFlowCtl = UART_HWCONTROL_NONE;
  huart4.Init.OverSampling = UART_OVERSAMPLING_16;
  huart4.Init.OneBitSampling = UART_ONE_BIT_SAMPLE_DISABLE;
  huart4.Init.ClockPrescaler = UART_PRESCALER_DIV1;
  huart4.AdvancedInit.AdvFeatureInit = UART_ADVFEATURE_NO_INIT;
  if (HAL_HalfDuplex_Init(&huart4) != HAL_OK)
  {
    Error_Handler();
  }
  if (HAL_UARTEx_SetTxFifoThreshold(&huart4, UART_TXFIFO_THRESHOLD_1_8) != HAL_OK)
  {
    Error_Handler();
  }
  if (HAL_UARTEx_SetRxFifoThreshold(&huart4, UART_RXFIFO_THRESHOLD_1_8) != HAL_OK)
  {
    Error_Handler();
  }
  if (HAL_UARTEx_DisableFifoMode(&huart4) != HAL_OK)
  {
    Error_Handler();
  }

}

static void MX_UART5_Init(void)
{

  huart5.Instance = UART5;
  huart5.Init.BaudRate = 115200;
  huart5.Init.WordLength = UART_WORDLENGTH_8B;
  huart5.Init.StopBits = UART_STOPBITS_1;
  huart5.Init.Parity = UART_PARITY_NONE;
  huart5.Init.Mode = UART_MODE_TX_RX;
  huart5.Init.HwFlowCtl = UART_HWCONTROL_NONE;
  huart5.Init.OverSampling = UART_OVERSAMPLING_16;
  huart5.Init.OneBitSampling = UART_ONE_BIT_SAMPLE_DISABLE;
  huart5.Init.ClockPrescaler = UART_PRESCALER_DIV1;
  huart5.AdvancedInit.AdvFeatureInit = UART_ADVFEATURE_NO_INIT;
  if (HAL_HalfDuplex_Init(&huart5) != HAL_OK)
  {
    Error_Handler();
  }
  if (HAL_UARTEx_SetTxFifoThreshold(&huart5, UART_TXFIFO_THRESHOLD_1_8) != HAL_OK)
  {
    Error_Handler();
  }
  if (HAL_UARTEx_SetRxFifoThreshold(&huart5, UART_RXFIFO_THRESHOLD_1_8) != HAL_OK)
  {
    Error_Handler();
  }
  if (HAL_UARTEx_DisableFifoMode(&huart5) != HAL_OK)
  {
    Error_Handler();
  }

}

static void MX_UART7_Init(void)
{

  huart7.Instance = UART7;
  huart7.Init.BaudRate = 115200;
  huart7.Init.WordLength = UART_WORDLENGTH_8B;
  huart7.Init.StopBits = UART_STOPBITS_1;
  huart7.Init.Parity = UART_PARITY_NONE;
  huart7.Init.Mode = UART_MODE_TX_RX;
  huart7.Init.HwFlowCtl = UART_HWCONTROL_NONE;
  huart7.Init.OverSampling = UART_OVERSAMPLING_16;
  huart7.Init.OneBitSampling = UART_ONE_BIT_SAMPLE_DISABLE;
  huart7.Init.ClockPrescaler = UART_PRESCALER_DIV1;
  huart7.AdvancedInit.AdvFeatureInit = UART_ADVFEATURE_NO_INIT;
  if (HAL_HalfDuplex_Init(&huart7) != HAL_OK)
  {
    Error_Handler();
  }
  if (HAL_UARTEx_SetTxFifoThreshold(&huart7, UART_TXFIFO_THRESHOLD_1_8) != HAL_OK)
  {
    Error_Handler();
  }
  if (HAL_UARTEx_SetRxFifoThreshold(&huart7, UART_RXFIFO_THRESHOLD_1_8) != HAL_OK)
  {
    Error_Handler();
  }
  if (HAL_UARTEx_DisableFifoMode(&huart7) != HAL_OK)
  {
    Error_Handler();
  }

}

static void MX_UART8_Init(void)
{

  huart8.Instance = UART8;
  huart8.Init.BaudRate = 115200;
  huart8.Init.WordLength = UART_WORDLENGTH_8B;
  huart8.Init.StopBits = UART_STOPBITS_1;
  huart8.Init.Parity = UART_PARITY_NONE;
  huart8.Init.Mode = UART_MODE_TX_RX;
  huart8.Init.HwFlowCtl = UART_HWCONTROL_NONE;
  huart8.Init.OverSampling = UART_OVERSAMPLING_16;
  huart8.Init.OneBitSampling = UART_ONE_BIT_SAMPLE_DISABLE;
  huart8.Init.ClockPrescaler = UART_PRESCALER_DIV1;
  huart8.AdvancedInit.AdvFeatureInit = UART_ADVFEATURE_NO_INIT;
  if (HAL_UART_Init(&huart8) != HAL_OK)
  {
    Error_Handler();
  }
  if (HAL_UARTEx_SetTxFifoThreshold(&huart8, UART_TXFIFO_THRESHOLD_1_8) != HAL_OK)
  {
    Error_Handler();
  }
  if (HAL_UARTEx_SetRxFifoThreshold(&huart8, UART_RXFIFO_THRESHOLD_1_8) != HAL_OK)
  {
    Error_Handler();
  }
  if (HAL_UARTEx_DisableFifoMode(&huart8) != HAL_OK)
  {
    Error_Handler();
  }

}

static void MX_USART1_UART_Init(void)
{

  huart1.Instance = USART1;
  huart1.Init.BaudRate = 115200;
  huart1.Init.WordLength = UART_WORDLENGTH_8B;
  huart1.Init.StopBits = UART_STOPBITS_1;
  huart1.Init.Parity = UART_PARITY_NONE;
  huart1.Init.Mode = UART_MODE_TX_RX;
  huart1.Init.HwFlowCtl = UART_HWCONTROL_NONE;
  huart1.Init.OverSampling = UART_OVERSAMPLING_16;
  huart1.Init.OneBitSampling = UART_ONE_BIT_SAMPLE_DISABLE;
  huart1.Init.ClockPrescaler = UART_PRESCALER_DIV1;
  huart1.AdvancedInit.AdvFeatureInit = UART_ADVFEATURE_NO_INIT;
  if (HAL_UART_Init(&huart1) != HAL_OK)
  {
    Error_Handler();
  }
  if (HAL_UARTEx_SetTxFifoThreshold(&huart1, UART_TXFIFO_THRESHOLD_1_8) != HAL_OK)
  {
    Error_Handler();
  }
  if (HAL_UARTEx_SetRxFifoThreshold(&huart1, UART_RXFIFO_THRESHOLD_1_8) != HAL_OK)
  {
    Error_Handler();
  }
  if (HAL_UARTEx_DisableFifoMode(&huart1) != HAL_OK)
  {
    Error_Handler();
  }

}

static void MX_USART2_UART_Init(void)
{

  huart2.Instance = USART2;
  huart2.Init.BaudRate = 115200;
  huart2.Init.WordLength = UART_WORDLENGTH_8B;
  huart2.Init.StopBits = UART_STOPBITS_1;
  huart2.Init.Parity = UART_PARITY_NONE;
  huart2.Init.Mode = UART_MODE_TX_RX;
  huart2.Init.HwFlowCtl = UART_HWCONTROL_NONE;
  huart2.Init.OverSampling = UART_OVERSAMPLING_16;
  huart2.Init.OneBitSampling = UART_ONE_BIT_SAMPLE_DISABLE;
  huart2.Init.ClockPrescaler = UART_PRESCALER_DIV1;
  huart2.AdvancedInit.AdvFeatureInit = UART_ADVFEATURE_NO_INIT;
  if (HAL_UART_Init(&huart2) != HAL_OK)
  {
    Error_Handler();
  }
  if (HAL_UARTEx_SetTxFifoThreshold(&huart2, UART_TXFIFO_THRESHOLD_1_8) != HAL_OK)
  {
    Error_Handler();
  }
  if (HAL_UARTEx_SetRxFifoThreshold(&huart2, UART_RXFIFO_THRESHOLD_1_8) != HAL_OK)
  {
    Error_Handler();
  }
  if (HAL_UARTEx_DisableFifoMode(&huart2) != HAL_OK)
  {
    Error_Handler();
  }

}

static void MX_USART3_UART_Init(void)
{

  huart3.Instance = USART3;
  huart3.Init.BaudRate = 1250000;
  huart3.Init.WordLength = UART_WORDLENGTH_9B;
  huart3.Init.StopBits = UART_STOPBITS_1;
  huart3.Init.Parity = UART_PARITY_EVEN;
  huart3.Init.Mode = UART_MODE_TX_RX;
  huart3.Init.HwFlowCtl = UART_HWCONTROL_NONE;
  huart3.Init.OverSampling = UART_OVERSAMPLING_16;
  huart3.Init.OneBitSampling = UART_ONE_BIT_SAMPLE_DISABLE;
  huart3.Init.ClockPrescaler = UART_PRESCALER_DIV1;
  huart3.AdvancedInit.AdvFeatureInit = UART_ADVFEATURE_NO_INIT;
  if (HAL_HalfDuplex_Init(&huart3) != HAL_OK)
  {
    Error_Handler();
  }
  if (HAL_UARTEx_SetTxFifoThreshold(&huart3, UART_TXFIFO_THRESHOLD_1_8) != HAL_OK)
  {
    Error_Handler();
  }
  if (HAL_UARTEx_SetRxFifoThreshold(&huart3, UART_RXFIFO_THRESHOLD_8_8) != HAL_OK)
  {
    Error_Handler();
  }
  if (HAL_UARTEx_EnableFifoMode(&huart3) != HAL_OK)
  {
    Error_Handler();
  }

}

static void MX_USART6_UART_Init(void)
{

  huart6.Instance = USART6;
  huart6.Init.BaudRate = 921600;
  huart6.Init.WordLength = UART_WORDLENGTH_8B;
  huart6.Init.StopBits = UART_STOPBITS_1;
  huart6.Init.Parity = UART_PARITY_NONE;
  huart6.Init.Mode = UART_MODE_TX_RX;
  huart6.Init.HwFlowCtl = UART_HWCONTROL_NONE;
  huart6.Init.OverSampling = UART_OVERSAMPLING_16;
  huart6.Init.OneBitSampling = UART_ONE_BIT_SAMPLE_DISABLE;
  huart6.Init.ClockPrescaler = UART_PRESCALER_DIV1;
  huart6.AdvancedInit.AdvFeatureInit = UART_ADVFEATURE_NO_INIT;
  if (HAL_UART_Init(&huart6) != HAL_OK)
  {
    Error_Handler();
  }
  if (HAL_UARTEx_SetTxFifoThreshold(&huart6, UART_TXFIFO_THRESHOLD_1_8) != HAL_OK)
  {
    Error_Handler();
  }
  if (HAL_UARTEx_SetRxFifoThreshold(&huart6, UART_RXFIFO_THRESHOLD_1_8) != HAL_OK)
  {
    Error_Handler();
  }
  if (HAL_UARTEx_DisableFifoMode(&huart6) != HAL_OK)
  {
    Error_Handler();
  }

}

static void MX_USB_OTG_HS_HCD_Init(void)
{

  hhcd_USB_OTG_HS.Instance = USB_OTG_HS;
  hhcd_USB_OTG_HS.Init.Host_channels = 16;
  hhcd_USB_OTG_HS.Init.speed = HCD_SPEED_FULL;
  hhcd_USB_OTG_HS.Init.dma_enable = DISABLE;
  hhcd_USB_OTG_HS.Init.phy_itface = USB_OTG_EMBEDDED_PHY;
  hhcd_USB_OTG_HS.Init.Sof_enable = DISABLE;
  hhcd_USB_OTG_HS.Init.low_power_enable = DISABLE;
  hhcd_USB_OTG_HS.Init.use_external_vbus = DISABLE;
  if (HAL_HCD_Init(&hhcd_USB_OTG_HS) != HAL_OK)
  {
    Error_Handler();
  }

}

static void MX_DMA_Init(void)
{

  /* DMA controller clock enable */
  __HAL_RCC_DMA1_CLK_ENABLE();

  /* DMA interrupt init */
  /* DMA1_Stream0_IRQn interrupt configuration */
  HAL_NVIC_SetPriority(DMA1_Stream0_IRQn, 5, 0);
  HAL_NVIC_EnableIRQ(DMA1_Stream0_IRQn);
  /* DMA1_Stream1_IRQn interrupt configuration */
  HAL_NVIC_SetPriority(DMA1_Stream1_IRQn, 5, 0);
  HAL_NVIC_EnableIRQ(DMA1_Stream1_IRQn);

}

static void MX_GPIO_Init(void)
{
  GPIO_InitTypeDef GPIO_InitStruct = {0};

  /* GPIO Ports Clock Enable */
  __HAL_RCC_GPIOC_CLK_ENABLE();
  __HAL_RCC_GPIOE_CLK_ENABLE();
  __HAL_RCC_GPIOB_CLK_ENABLE();
  __HAL_RCC_GPIOA_CLK_ENABLE();
  __HAL_RCC_GPIOD_CLK_ENABLE();
  __HAL_RCC_GPIOH_CLK_ENABLE();

  /*Configure GPIO pin Output Level */
  HAL_GPIO_WritePin(IMU_nCS_GPIO_Port, IMU_nCS_Pin, GPIO_PIN_SET);

  /*Configure GPIO pin Output Level */
  HAL_GPIO_WritePin(BARO_CS_GPIO_Port, BARO_CS_Pin, GPIO_PIN_SET);

  /*Configure GPIO pin Output Level */
  HAL_GPIO_WritePin(GPIOD, IFSPI_nCS_Pin|WRITE_AUX_Pin|LED1_Pin|LED2_Pin, GPIO_PIN_RESET);

  /*Configure GPIO pin : IMU_nCS_Pin */
  GPIO_InitStruct.Pin = IMU_nCS_Pin;
  GPIO_InitStruct.Mode = GPIO_MODE_OUTPUT_PP;
  GPIO_InitStruct.Pull = GPIO_NOPULL;
  GPIO_InitStruct.Speed = GPIO_SPEED_FREQ_LOW;
  HAL_GPIO_Init(IMU_nCS_GPIO_Port, &GPIO_InitStruct);

  /*Configure GPIO pin : BARO_CS_Pin */
  GPIO_InitStruct.Pin = BARO_CS_Pin;
  GPIO_InitStruct.Mode = GPIO_MODE_OUTPUT_PP;
  GPIO_InitStruct.Pull = GPIO_NOPULL;
  GPIO_InitStruct.Speed = GPIO_SPEED_FREQ_LOW;
  HAL_GPIO_Init(BARO_CS_GPIO_Port, &GPIO_InitStruct);

  /*Configure GPIO pins : IFSPI_nCS_Pin WRITE_AUX_Pin LED1_Pin LED2_Pin */
  GPIO_InitStruct.Pin = IFSPI_nCS_Pin|WRITE_AUX_Pin|LED1_Pin|LED2_Pin;
  GPIO_InitStruct.Mode = GPIO_MODE_OUTPUT_PP;
  GPIO_InitStruct.Pull = GPIO_NOPULL;
  GPIO_InitStruct.Speed = GPIO_SPEED_FREQ_LOW;
  HAL_GPIO_Init(GPIOD, &GPIO_InitStruct);

  /*Configure GPIO pin : IFIO1_Pin */
  GPIO_InitStruct.Pin = IFIO1_Pin;
  GPIO_InitStruct.Mode = GPIO_MODE_INPUT;
  GPIO_InitStruct.Pull = GPIO_NOPULL;
  HAL_GPIO_Init(IFIO1_GPIO_Port, &GPIO_InitStruct);

  /*Configure GPIO pins : IFIO2_Pin IFIO3_Pin IFIO4_Pin */
  GPIO_InitStruct.Pin = IFIO2_Pin|IFIO3_Pin|IFIO4_Pin;
  GPIO_InitStruct.Mode = GPIO_MODE_INPUT;
  GPIO_InitStruct.Pull = GPIO_NOPULL;
  HAL_GPIO_Init(GPIOD, &GPIO_InitStruct);

}

__weak void coretaskFunc(void const * argument)
{
  /* init code for LWIP */
  //MX_LWIP_Init();
  for(;;)
  {
    osDelay(1);
  }
}

__weak void rosSpinTaskFunc(void const * argument)
{
  for(;;)
  {
    osDelay(1);
  }
}

__weak void idleTaskFunc(void const * argument)
{
  for(;;)
  {
    osDelay(1);
  }
}

__weak void rosPubliushTask(void const * argument)
{
  for(;;)
  {
    osDelay(1);
  }
}

void voltageTask(void const * argument)
{
  for(;;)
  {
    osDelay(1);
  }
}

/* coreTaskEvokeCb function */
void coreTaskEvokeCb(void const * argument)
{
}

/* MPU Configuration */

void MPU_Config(void)
{
  MPU_Region_InitTypeDef MPU_InitStruct = {0};

  /* Disables the MPU */
  HAL_MPU_Disable();
  /** Initializes and configures the Region and the memory to be protected
  */
  MPU_InitStruct.Enable = MPU_REGION_ENABLE;
  MPU_InitStruct.Number = MPU_REGION_NUMBER0;
  MPU_InitStruct.BaseAddress = 0x24040000;
  MPU_InitStruct.Size = MPU_REGION_SIZE_1KB;
  MPU_InitStruct.SubRegionDisable = 0x0;
  MPU_InitStruct.TypeExtField = MPU_TEX_LEVEL1;
  MPU_InitStruct.AccessPermission = MPU_REGION_FULL_ACCESS;
  MPU_InitStruct.DisableExec = MPU_INSTRUCTION_ACCESS_ENABLE;
  MPU_InitStruct.IsShareable = MPU_ACCESS_NOT_SHAREABLE;
  MPU_InitStruct.IsCacheable = MPU_ACCESS_NOT_CACHEABLE;
  MPU_InitStruct.IsBufferable = MPU_ACCESS_NOT_BUFFERABLE;

  HAL_MPU_ConfigRegion(&MPU_InitStruct);
  /** Initializes and configures the Region and the memory to be protected
  */
  MPU_InitStruct.Enable = MPU_REGION_ENABLE;
  MPU_InitStruct.Number = MPU_REGION_NUMBER1;
  MPU_InitStruct.BaseAddress = 0x24040000;
  MPU_InitStruct.Size = MPU_REGION_SIZE_16KB;
  MPU_InitStruct.SubRegionDisable = 0x0;
  MPU_InitStruct.TypeExtField = MPU_TEX_LEVEL0;
  MPU_InitStruct.AccessPermission = MPU_REGION_FULL_ACCESS;
  MPU_InitStruct.DisableExec = MPU_INSTRUCTION_ACCESS_ENABLE;
  MPU_InitStruct.IsShareable = MPU_ACCESS_SHAREABLE;
  MPU_InitStruct.IsCacheable = MPU_ACCESS_CACHEABLE;
  MPU_InitStruct.IsBufferable = MPU_ACCESS_NOT_BUFFERABLE;

  HAL_MPU_ConfigRegion(&MPU_InitStruct);
  /** Initializes and configures the Region and the memory to be protected
  */
  MPU_InitStruct.Enable = MPU_REGION_ENABLE;
  MPU_InitStruct.Number = MPU_REGION_NUMBER2;
  MPU_InitStruct.BaseAddress = 0x24044400;
  MPU_InitStruct.Size = MPU_REGION_SIZE_16KB;
  MPU_InitStruct.SubRegionDisable = 0x0;
  MPU_InitStruct.TypeExtField = MPU_TEX_LEVEL1;
  MPU_InitStruct.AccessPermission = MPU_REGION_FULL_ACCESS;
  MPU_InitStruct.DisableExec = MPU_INSTRUCTION_ACCESS_ENABLE;
  MPU_InitStruct.IsShareable = MPU_ACCESS_NOT_SHAREABLE;
  MPU_InitStruct.IsCacheable = MPU_ACCESS_NOT_CACHEABLE;
  MPU_InitStruct.IsBufferable = MPU_ACCESS_NOT_BUFFERABLE;

  HAL_MPU_ConfigRegion(&MPU_InitStruct);
  /** Initializes and configures the Region and the memory to be protected
  */
  MPU_InitStruct.Enable = MPU_REGION_ENABLE;
  MPU_InitStruct.Number = MPU_REGION_NUMBER3;
  MPU_InitStruct.BaseAddress = 0x30040000;
  MPU_InitStruct.Size = MPU_REGION_SIZE_16KB;
  MPU_InitStruct.SubRegionDisable = 0x0;
  MPU_InitStruct.TypeExtField = MPU_TEX_LEVEL1;
  MPU_InitStruct.AccessPermission = MPU_REGION_FULL_ACCESS;
  MPU_InitStruct.DisableExec = MPU_INSTRUCTION_ACCESS_ENABLE;
  MPU_InitStruct.IsShareable = MPU_ACCESS_NOT_SHAREABLE;
  MPU_InitStruct.IsCacheable = MPU_ACCESS_NOT_CACHEABLE;
  MPU_InitStruct.IsBufferable = MPU_ACCESS_NOT_BUFFERABLE;

  HAL_MPU_ConfigRegion(&MPU_InitStruct);
  /** Initializes and configures the Region and the memory to be protected
  */
  MPU_InitStruct.Enable = MPU_REGION_ENABLE;
  MPU_InitStruct.Number = MPU_REGION_NUMBER4;
  MPU_InitStruct.BaseAddress = 0x30044000;
  MPU_InitStruct.Size = MPU_REGION_SIZE_16KB;
  MPU_InitStruct.SubRegionDisable = 0x0;
  MPU_InitStruct.TypeExtField = MPU_TEX_LEVEL0;
  MPU_InitStruct.AccessPermission = MPU_REGION_FULL_ACCESS;
  MPU_InitStruct.DisableExec = MPU_INSTRUCTION_ACCESS_ENABLE;
  MPU_InitStruct.IsShareable = MPU_ACCESS_NOT_SHAREABLE;
  MPU_InitStruct.IsCacheable = MPU_ACCESS_CACHEABLE;
  MPU_InitStruct.IsBufferable = MPU_ACCESS_NOT_BUFFERABLE;

  HAL_MPU_ConfigRegion(&MPU_InitStruct);
  /** Initializes and configures the Region and the memory to be protected
  */
  MPU_InitStruct.Enable = MPU_REGION_ENABLE;
  MPU_InitStruct.Number = MPU_REGION_NUMBER5;
  MPU_InitStruct.BaseAddress = 0x30040000;
  MPU_InitStruct.Size = MPU_REGION_SIZE_256B;
  MPU_InitStruct.SubRegionDisable = 0x0;
  MPU_InitStruct.TypeExtField = MPU_TEX_LEVEL0;
  MPU_InitStruct.AccessPermission = MPU_REGION_FULL_ACCESS;
  MPU_InitStruct.DisableExec = MPU_INSTRUCTION_ACCESS_ENABLE;
  MPU_InitStruct.IsShareable = MPU_ACCESS_NOT_SHAREABLE;
  MPU_InitStruct.IsCacheable = MPU_ACCESS_NOT_CACHEABLE;
  MPU_InitStruct.IsBufferable = MPU_ACCESS_BUFFERABLE;

  HAL_MPU_ConfigRegion(&MPU_InitStruct);
  /** Initializes and configures the Region and the memory to be protected
  */
  MPU_InitStruct.Enable = MPU_REGION_ENABLE;
  MPU_InitStruct.Number = MPU_REGION_NUMBER6;
  MPU_InitStruct.BaseAddress = 0x24044800;
  MPU_InitStruct.Size = MPU_REGION_SIZE_1KB;
  MPU_InitStruct.SubRegionDisable = 0x0;
  MPU_InitStruct.TypeExtField = MPU_TEX_LEVEL1;
  MPU_InitStruct.AccessPermission = MPU_REGION_FULL_ACCESS;
  MPU_InitStruct.DisableExec = MPU_INSTRUCTION_ACCESS_ENABLE;
  MPU_InitStruct.IsShareable = MPU_ACCESS_NOT_SHAREABLE;
  MPU_InitStruct.IsCacheable = MPU_ACCESS_NOT_CACHEABLE;
  MPU_InitStruct.IsBufferable = MPU_ACCESS_NOT_BUFFERABLE;

  HAL_MPU_ConfigRegion(&MPU_InitStruct);
  /** Initializes and configures the Region and the memory to be protected
  */
  MPU_InitStruct.Enable = MPU_REGION_ENABLE;
  MPU_InitStruct.Number = MPU_REGION_NUMBER7;
  MPU_InitStruct.BaseAddress = 0x24044C00;
  MPU_InitStruct.Size = MPU_REGION_SIZE_1KB;
  MPU_InitStruct.SubRegionDisable = 0x0;
  MPU_InitStruct.TypeExtField = MPU_TEX_LEVEL1;
  MPU_InitStruct.AccessPermission = MPU_REGION_FULL_ACCESS;
  MPU_InitStruct.DisableExec = MPU_INSTRUCTION_ACCESS_ENABLE;
  MPU_InitStruct.IsShareable = MPU_ACCESS_NOT_SHAREABLE;
  MPU_InitStruct.IsCacheable = MPU_ACCESS_NOT_CACHEABLE;
  MPU_InitStruct.IsBufferable = MPU_ACCESS_NOT_BUFFERABLE;

  HAL_MPU_ConfigRegion(&MPU_InitStruct);
  /** Initializes and configures the Region and the memory to be protected
  */
  MPU_InitStruct.Enable = MPU_REGION_ENABLE;
  MPU_InitStruct.Number = MPU_REGION_NUMBER8;
  MPU_InitStruct.BaseAddress = 0x24045000;
  MPU_InitStruct.Size = MPU_REGION_SIZE_128B;
  MPU_InitStruct.SubRegionDisable = 0x0;
  MPU_InitStruct.TypeExtField = MPU_TEX_LEVEL0;
  MPU_InitStruct.AccessPermission = MPU_REGION_NO_ACCESS;
  MPU_InitStruct.DisableExec = MPU_INSTRUCTION_ACCESS_ENABLE;
  MPU_InitStruct.IsShareable = MPU_ACCESS_NOT_SHAREABLE;
  MPU_InitStruct.IsCacheable = MPU_ACCESS_NOT_CACHEABLE;
  MPU_InitStruct.IsBufferable = MPU_ACCESS_NOT_BUFFERABLE;

  HAL_MPU_ConfigRegion(&MPU_InitStruct);
  /** Initializes and configures the Region and the memory to be protected
  */
  MPU_InitStruct.Enable = MPU_REGION_ENABLE;
  MPU_InitStruct.Number = MPU_REGION_NUMBER9;
  MPU_InitStruct.BaseAddress = 0x24045080;
  MPU_InitStruct.Size = MPU_REGION_SIZE_128B;
  MPU_InitStruct.SubRegionDisable = 0x0;
  MPU_InitStruct.TypeExtField = MPU_TEX_LEVEL0;
  MPU_InitStruct.AccessPermission = MPU_REGION_FULL_ACCESS;
  MPU_InitStruct.DisableExec = MPU_INSTRUCTION_ACCESS_ENABLE;
  MPU_InitStruct.IsShareable = MPU_ACCESS_NOT_SHAREABLE;
  MPU_InitStruct.IsCacheable = MPU_ACCESS_NOT_CACHEABLE;
  MPU_InitStruct.IsBufferable = MPU_ACCESS_NOT_BUFFERABLE;

  HAL_MPU_ConfigRegion(&MPU_InitStruct);
  /** Initializes and configures the Region and the memory to be protected
  */
  MPU_InitStruct.Enable = MPU_REGION_ENABLE;
  MPU_InitStruct.Number = MPU_REGION_NUMBER10;
  MPU_InitStruct.BaseAddress = 0x24045100;
  MPU_InitStruct.Size = MPU_REGION_SIZE_128B;
  MPU_InitStruct.SubRegionDisable = 0x0;
  MPU_InitStruct.TypeExtField = MPU_TEX_LEVEL0;
  MPU_InitStruct.AccessPermission = MPU_REGION_FULL_ACCESS;
  MPU_InitStruct.DisableExec = MPU_INSTRUCTION_ACCESS_ENABLE;
  MPU_InitStruct.IsShareable = MPU_ACCESS_NOT_SHAREABLE;
  MPU_InitStruct.IsCacheable = MPU_ACCESS_NOT_CACHEABLE;
  MPU_InitStruct.IsBufferable = MPU_ACCESS_NOT_BUFFERABLE;

  HAL_MPU_ConfigRegion(&MPU_InitStruct);
  /** Initializes and configures the Region and the memory to be protected
  */
  MPU_InitStruct.Enable = MPU_REGION_ENABLE;
  MPU_InitStruct.Number = MPU_REGION_NUMBER11;
  MPU_InitStruct.BaseAddress = 0x24045180;
  MPU_InitStruct.Size = MPU_REGION_SIZE_128B;
  MPU_InitStruct.SubRegionDisable = 0x0;
  MPU_InitStruct.TypeExtField = MPU_TEX_LEVEL0;
  MPU_InitStruct.AccessPermission = MPU_REGION_FULL_ACCESS;
  MPU_InitStruct.DisableExec = MPU_INSTRUCTION_ACCESS_ENABLE;
  MPU_InitStruct.IsShareable = MPU_ACCESS_NOT_SHAREABLE;
  MPU_InitStruct.IsCacheable = MPU_ACCESS_NOT_CACHEABLE;
  MPU_InitStruct.IsBufferable = MPU_ACCESS_NOT_BUFFERABLE;

  HAL_MPU_ConfigRegion(&MPU_InitStruct);
  /* Enables the MPU */
  HAL_MPU_Enable(MPU_PRIVILEGED_DEFAULT);

}
void HAL_TIM_PeriodElapsedCallback(TIM_HandleTypeDef *htim)
{
  if (htim->Instance == TIM8) {
    HAL_IncTick();
  }
}

void Error_Handler(void)
{
  __disable_irq();
  while (1)
  {
  }
}

/************************ (C) COPYRIGHT STMicroelectronics *****END OF FILE****/

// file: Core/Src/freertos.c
/* USER CODE BEGIN Header */
/**
  ******************************************************************************
  * File Name          : freertos.c
  * Description        : Code for freertos applications
  ******************************************************************************
  * @attention
  *
  * <h2><center>&copy; Copyright (c) 2025 STMicroelectronics.
  * All rights reserved.</center></h2>
  *
  * This software component is licensed by ST under Ultimate Liberty license
  * SLA0044, the "License"; You may not use this file except in compliance with
  * the License. You may obtain a copy of the License at:
  *                             www.st.com/SLA0044
  *
  ******************************************************************************
  */
/* USER CODE END Header */

#include "FreeRTOS.h"
#include "task.h"
#include "main.h"

/* GetIdleTaskMemory prototype (linked to static allocation support) */
void vApplicationGetIdleTaskMemory( StaticTask_t **ppxIdleTaskTCBBuffer, StackType_t **ppxIdleTaskStackBuffer, uint32_t *pulIdleTaskStackSize );

/* GetTimerTaskMemory prototype (linked to static allocation support) */
void vApplicationGetTimerTaskMemory( StaticTask_t **ppxTimerTaskTCBBuffer, StackType_t **ppxTimerTaskStackBuffer, uint32_t *pulTimerTaskStackSize );

/* USER CODE BEGIN GET_IDLE_TASK_MEMORY */
static StaticTask_t xIdleTaskTCBBuffer;
static StackType_t xIdleStack[configMINIMAL_STACK_SIZE];

void vApplicationGetIdleTaskMemory( StaticTask_t **ppxIdleTaskTCBBuffer, StackType_t **ppxIdleTaskStackBuffer, uint32_t *pulIdleTaskStackSize )
{
  *ppxIdleTaskTCBBuffer = &xIdleTaskTCBBuffer;
  *ppxIdleTaskStackBuffer = &xIdleStack[0];
  *pulIdleTaskStackSize = configMINIMAL_STACK_SIZE;
  /* place for user code */
}
/* USER CODE END GET_IDLE_TASK_MEMORY */

/* USER CODE BEGIN GET_TIMER_TASK_MEMORY */
static StaticTask_t xTimerTaskTCBBuffer;
static StackType_t xTimerStack[configTIMER_TASK_STACK_DEPTH];

void vApplicationGetTimerTaskMemory( StaticTask_t **ppxTimerTaskTCBBuffer, StackType_t **ppxTimerTaskStackBuffer, uint32_t *pulTimerTaskStackSize )
{
  *ppxTimerTaskTCBBuffer = &xTimerTaskTCBBuffer;
  *ppxTimerTaskStackBuffer = &xTimerStack[0];
  *pulTimerTaskStackSize = configTIMER_TASK_STACK_DEPTH;
  /* place for user code */
}
/* USER CODE END GET_TIMER_TASK_MEMORY */

/************************ (C) COPYRIGHT STMicroelectronics *****END OF FILE****/
